# GT32U2086 register map
Vendor: FPTTelecom
Registers are 32-bit, read-write, reset 0x0 unless marked. A register's access mark holds for its fields unless they carry their own. Offsets are from the block's base; [hi:lo] are bit positions; {n}, {i} and the like mark numbered series.

## GPIOC — GPIOC - GENERAL PURPOSE INPUT OUTPUT PORT C GPIOC : 0x440F0000 - 0x440FFFFF (64 KB)
Base 0x440F0000
Same registers: GPIOD 0x44100000, GPIOE 0x44110000, GPIOF 0x44120000, GPIOA 0x50030000, GPIOB 0x50040000
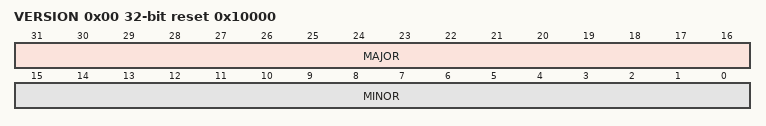
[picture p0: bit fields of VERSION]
0x00 VERSION ro reset 0x10000 — GPIO Version Register bit[15:0] MINOR | bit[31:16] MAJOR
  [31:16] MAJOR — Major version number in bits [31:16]
  [15:0] MINOR — Minor version number in bits [15:0]
0x10 OE — GPIO Output Enable Register bit[7:0] EN
  [7:0] EN — Output enable for GPIO[7:0]: 0=input, 1=output
0x14 OUT — GPIO Output Data Register bit[7:0] OUT
  [7:0] OUT — Output data for GPIO[7:0]
0x18 IN ro — GPIO Input Data Register bit[7:0] IN
  [7:0] IN — Input data for GPIO[7:0]
0x1C CTL — GPIO Control Register bit[7:0] SYNC_EN
  [7:0] SYNC_EN — Enable the input synchronizer for GPIO[7:0]: 0=direct path, 1=through a synchronizing flip-flop
0x20 RAW_INT — GPIO Raw Interrupt Status Register bit[7:0] INTR_A; W1C
  [7:0] INTR_A — Raw GPIO[7:0] interrupt flags; write 1 to clear the corresponding flag
0x24 INT_STA ro — GPIO Interrupt Status Register bit[7:0] INTR_A
  [7:0] INTR_A — Masked interrupt status for GPIO[7:0]
0x28 INT_EN — GPIO Interrupt Enable Register bit[7:0] INTR_A
  [7:0] INTR_A — Enable interrupts for GPIO[7:0]
0x2C INT_INJ — GPIO Interrupt Injection Register bit[7:0] INTR_A
  [7:0] INTR_A — Inject interrupts for GPIO[7:0]
0x3FC DATA_ALL — PL061-compatible all-pin data alias bit[7:0] DATA

## FLASH_CTRL — FLASH_CTRL - FLASH CONTROLLER FLASH_CTRL : 0x50000000 - 0x5000FFFF (64 KB) Reference: GT32U2086 Common Specification v8 / FLASH controller v1.4
Base 0x50000000
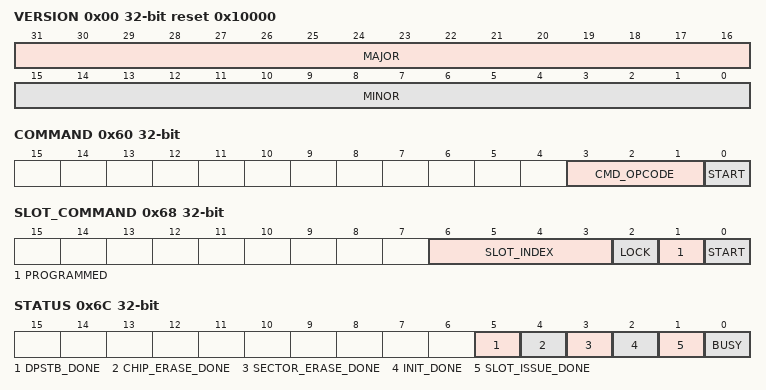
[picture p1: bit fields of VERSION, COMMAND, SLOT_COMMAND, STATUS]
0x00 VERSION ro reset 0x10000 — Version Register bit[15:0] MINOR_VERSION | bit[31:16] MAJOR_VERSION
  [31:16] MAJOR — Major version
  [15:0] MINOR — Minor version
0x10 SET0_RD_TIMING reset 0x2224 — Set-0 read timing
0x14 SET0_CFG_TIMING reset 0x222 — Set-0 configuration timing
0x18 SET0_PROG_TIMING0 reset 0x78008A — Set-0 program timing 0
0x1C SET0_PROG_TIMING1 reset 0x222008F — Set-0 program timing 1
0x20 SET0_PROG_TIMING2 reset 0xF803 — Set-0 program timing 2
0x24 SET0_ERASE_TIMING0 reset 0x3
0x28 SET0_SECTOR_ERASE_TIMING reset 0x26B182B8
0x2C SET0_CHIP_RCV reset 0x1356 — Set-0 chip erase recovery
0x30 SET0_CHIP_ERASE reset 0xBBFD0 — Set-0 chip erase timing
0x34 SET0_DPSTB_TIMING reset 0x50 — Set-0 deep-power standby timing
0x38 SET1_RD_TIMING reset 0x3334 — Set-1 read timing
0x3C SET1_CFG_TIMING reset 0x444 — Set-1 configuration timing
0x40 SET1_PROG_TIMING0 reset 0x1E001F4 — Set-1 program timing 0
0x44 SET1_PROG_TIMING1 reset 0x2220208 — Set-1 program timing 1
0x48 SET1_PROG_TIMING2 reset 0x38409 — Set-1 program timing 2
0x4C SET1_ERASE_TIMING0 reset 0x9
0x50 SET1_SECTOR_ERASE_TIMING reset 0x8CA57E40
0x54 SET1_CHIP_RCV reset 0x4650 — Set-1 chip erase recovery
0x58 SET1_CHIP_ERASE reset 0x2AB980 — Set-1 chip erase timing
0x5C SET1_DPSTB_TIMING reset 0x122 — Set-1 deep-power standby timing
0x60 COMMAND — Command register bit[0] START | bit[3:1] CMD_OPCODE
  [3:1] CMD_OPCODE — 1=INIT, 2=SECTOR_ERASE, 3=CHIP_ERASE, 5=DPSTB_ENTRY, 6=DPSTB_EXIT
  [0] START — Start command; hardware clears it on completion
0x64 CMD_ADDR — Logical SoC address used by erase commands
0x68 SLOT_COMMAND — NVR slot command bit[0] START | bit[1] PROGRAMMED | bit[2] LOCK | bit[6:3] SLOT_INDEX
  [6:3] SLOT_INDEX — NVR slot index 0 through 13
  [2] LOCK — Lock value
  [1] PROGRAMMED — Programmed value
  [0] START — Start slot command
0x6C STATUS ro — Command engine status
  [5] DPSTB_DONE — Deep-power standby exit complete
  [4] CHIP_ERASE_DONE — Chip erase complete
  [3] SECTOR_ERASE_DONE — Sector erase complete
  [2] INIT_DONE — Initialization complete
  [1] SLOT_ISSUE_DONE — NVR slot command complete
  [0] BUSY — Command engine busy

## ADC — ADC - GT32U2086 v8 23-register ADC controller.
Base 0x500A0000
0x00 VERSION ro reset 0x10000 — Version: minor[15:0], major[31:16]
0x04 CTRL — ADC control
  [0] ADC_EN — Enable ADC conversion
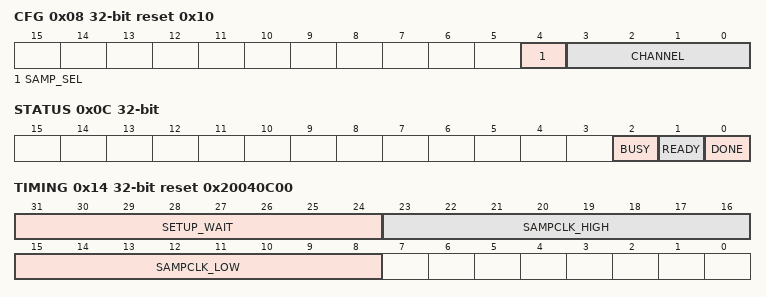
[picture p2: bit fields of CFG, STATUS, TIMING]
0x08 CFG reset 0x10 — Channel and sample selection
  [4] SAMP_SEL — Sample source selection
  [3:0] CHANNEL — Input channel
0x0C STATUS ro — Conversion status
  [2] BUSY — Conversion busy
  [1] READY — Result ready
  [0] DONE — Conversion complete
0x10 DATA ro — 12-bit averaged conversion data
0x14 TIMING reset 0x20040C00 — ADC timing configuration
  [31:24] SETUP_WAIT — Setup wait time
  [23:16] SAMPCLK_HIGH — Sample clock high time
  [15:8] SAMPCLK_LOW — Sample clock low time
0x18 SAMPLE_CFG reset 0x1 — Sample averaging count
  [4:0] SAMPLE_COUNT — Number of samples
{0x1C+4i} SAMPLE{i} ro (i=0..15) — 12-bit sample slot {i}

## RTC — RTC - REAL TIME CLOCK RTC : 0x500F0000 - 0x500FFFFF (64 KB) Reference: dti_rtc_ug_rev1p0.pdf
Base 0x500F0000
0x00 RTIME ro — Current time register (BCD) bit[7:0] MILLISECOND | bit[14:8] SECOND | bit[21:15] MINUTE | bit[27:22] HOUR
0x04 RDATE ro — Current date register (BCD) bit[5:0] DATE | bit[9:6] DAY | bit[14:10] MONTH | bit[30:15] YEAR
0x08 TIMECFG — Time configuration register bit[6:0] SECOND | bit[13:7] MINUTE | bit[19:14] HOUR
0x0C DATECFG — Date configuration register bit[5:0] DATE | bit[10:6] MONTH | bit[26:11] YEAR
0x10 CPSR reset 0x2710 — Counter prescaler register bit[25:0] DIV | bit[29:26] DLF_VALUE | bit[30] DLF_EN | bit[31] RTC_EN
0x14 ALAR0 — Alarm 0 duration register bit[15:0] ALARM_TIME
0x18 ALAR1_INS0 — Alarm 1 channel 0 register bit[6:0] ALARM_SECOND | bit[13:7] ALARM_MINUTE | bit[19:14] ALARM_HOUR | bit[20] ALARM_EN | bit[21] ALARM_ON; ALARM_ON bit[21] is RO
0x1C ALAR1_INS1 — Alarm 1 channel 1 register bit[6:0] ALARM_SECOND | bit[13:7] ALARM_MINUTE | bit[19:14] ALARM_HOUR | bit[20] ALARM_EN | bit[21] ALARM_ON; ALARM_ON bit[21] is RO
0x20 INTR_INS0 — Event interrupt channel 0 register bit[7:0] INT_SECOND | bit[15:8] INT_MINUTE | bit[23:16] INT_HOUR | bit[24] INT_EN
0x24 INTR_INS1 — Event interrupt channel 1 register bit[7:0] INT_SECOND | bit[15:8] INT_MINUTE | bit[23:16] INT_HOUR | bit[24] INT_EN
0x28 CSTW reset 0x2 — Control stopwatch register bit[0] ENABLE | bit[1] AUTO_SAVE
0x2C RSTW — Reset stopwatch register bit[0] RESET
0x30 CTSTW — Capture stopwatch register bit[0] CAPTURE
0x34 TSTW ro — Captured stopwatch time register (BCD) bit[7:0] MILLISECOND | bit[14:8] SECOND | bit[21:15] MINUTE | bit[29:22] HOUR
0x38 STT ro — Status register bit[0] INT_TXFF_FULL | bit[1] INT_TXFF_EMPTY
0x3C CLKS ro — Clock status register (Read-to-Clear) bit[0] CLK_FAILURE | bit[8:1] ADDR_FAILURE | bit[9] CMD_FAILURE; read-to-clear
